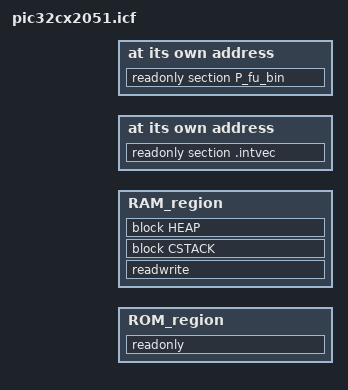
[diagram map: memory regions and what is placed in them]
/* ---------------------------------------------------------------------------- */
/*                Microchip Microcontroller Software Support                    */
/*                       SAM Software Package License                           */
/* ---------------------------------------------------------------------------- */
/* Copyright (c) 2021, Microchip Technology Inc.                                */
/*                                                                              */
/* All rights reserved.                                                         */
/*                                                                              */
/* Redistribution and use in source and binary forms, with or without           */
/* modification, are permitted provided that the following condition is met:    */
/*                                                                              */
/* - Redistributions of source code must retain the above copyright notice,     */
/* this list of conditions and the disclaimer below.                            */
/*                                                                              */
/* Microchip's name may not be used to endorse or promote products derived from */
/* this software without specific prior written permission.                     */
/*                                                                              */
/* DISCLAIMER:  THIS SOFTWARE IS PROVIDED BY MICROCHIP "AS IS" AND ANY EXPRESS  */
/* OR IMPLIED WARRANTIES, INCLUDING, BUT NOT LIMITED TO, THE IMPLIED WARRANTIES */
/* OF MERCHANTABILITY, FITNESS FOR A PARTICULAR PURPOSE AND NON-INFRINGEMENT    */
/* ARE DISCLAIMED. IN NO EVENT SHALL MICROCHIP BE LIABLE FOR ANY DIRECT,        */
/* INDIRECT, INCIDENTAL, SPECIAL, EXEMPLARY, OR CONSEQUENTIAL DAMAGES           */
/* (INCLUDING, BUT NOT LIMITED TO, PROCUREMENT OF SUBSTITUTE GOODS OR SERVICES; */
/* LOSS OF USE, DATA, OR PROFITS; OR BUSINESS INTERRUPTION) HOWEVER CAUSED AND  */
/* ON ANY THEORY OF LIABILITY, WHETHER IN CONTRACT, STRICT LIABILITY, OR TORT   */
/* (INCLUDING NEGLIGENCE OR OTHERWISE) ARISING IN ANY WAY OUT OF THE USE OF     */
/* THIS SOFTWARE, EVEN IF ADVISED OF THE POSSIBILITY OF SUCH DAMAGE.            */
/* ---------------------------------------------------------------------------- */

/*###ICF### Section handled by ICF editor, don't touch! ****/
/*-Editor annotation file-*/
/* IcfEditorFile="$TOOLKIT_DIR$\config\ide\IcfEditor\cortex_v1_0.xml" */

/* Tools provide -DMBED_ROM_START=xxx -DMBED_ROM_SIZE=xxx -DMBED_RAM_START=xxx -DMBED_RAM_SIZE=xxx */

/* 16+97 vect */
define symbol VECTORS     = 113;
define symbol HEAP_SIZE   = 0x10000;

/* Common - Do not change */
if (!isdefinedsymbol(MBED_APP_START)) {
    define symbol MBED_APP_START = MBED_ROM_START;
}

if (!isdefinedsymbol(MBED_APP_SIZE)) {
    define symbol MBED_APP_SIZE = MBED_ROM_SIZE;
}

if (!isdefinedsymbol(MBED_BOOT_STACK_SIZE)) {
    /* This value is normally defined by the tools
        to 0x1000 for bare metal and 0x400 for RTOS */
    define symbol MBED_BOOT_STACK_SIZE = 0x400;
}

/* Round up VECTORS_SIZE to 8 bytes */
define symbol VECTORS_SIZE = ((VECTORS * 4) + 7) & ~7;
define symbol RAM_REGION_START = MBED_RAM_START + VECTORS_SIZE;
define symbol RAM_REGION_SIZE = MBED_RAM_SIZE - VECTORS_SIZE;

define memory mem with size = 4G;
define region ROM_region = mem:[from MBED_APP_START size MBED_APP_SIZE];
define region RAM_region = mem:[from RAM_REGION_START size RAM_REGION_SIZE];

define block CSTACK    with alignment = 8, size = MBED_BOOT_STACK_SIZE   { };
define block HEAP      with alignment = 8, size = HEAP_SIZE     { };

initialize by copy { readwrite };
do not initialize  { section .noinit };

place at address mem: MBED_APP_START  { readonly section .intvec };

place in ROM_region     { readonly };
place in RAM_region     { readwrite, block CSTACK, block HEAP };

define symbol FU_REGION_SIZE = 0x40000;
define symbol FU_REGION_START = MBED_ROM_START + MBED_ROM_SIZE - FU_REGION_SIZE;
place at address mem: FU_REGION_START      { readonly section P_fu_bin };
